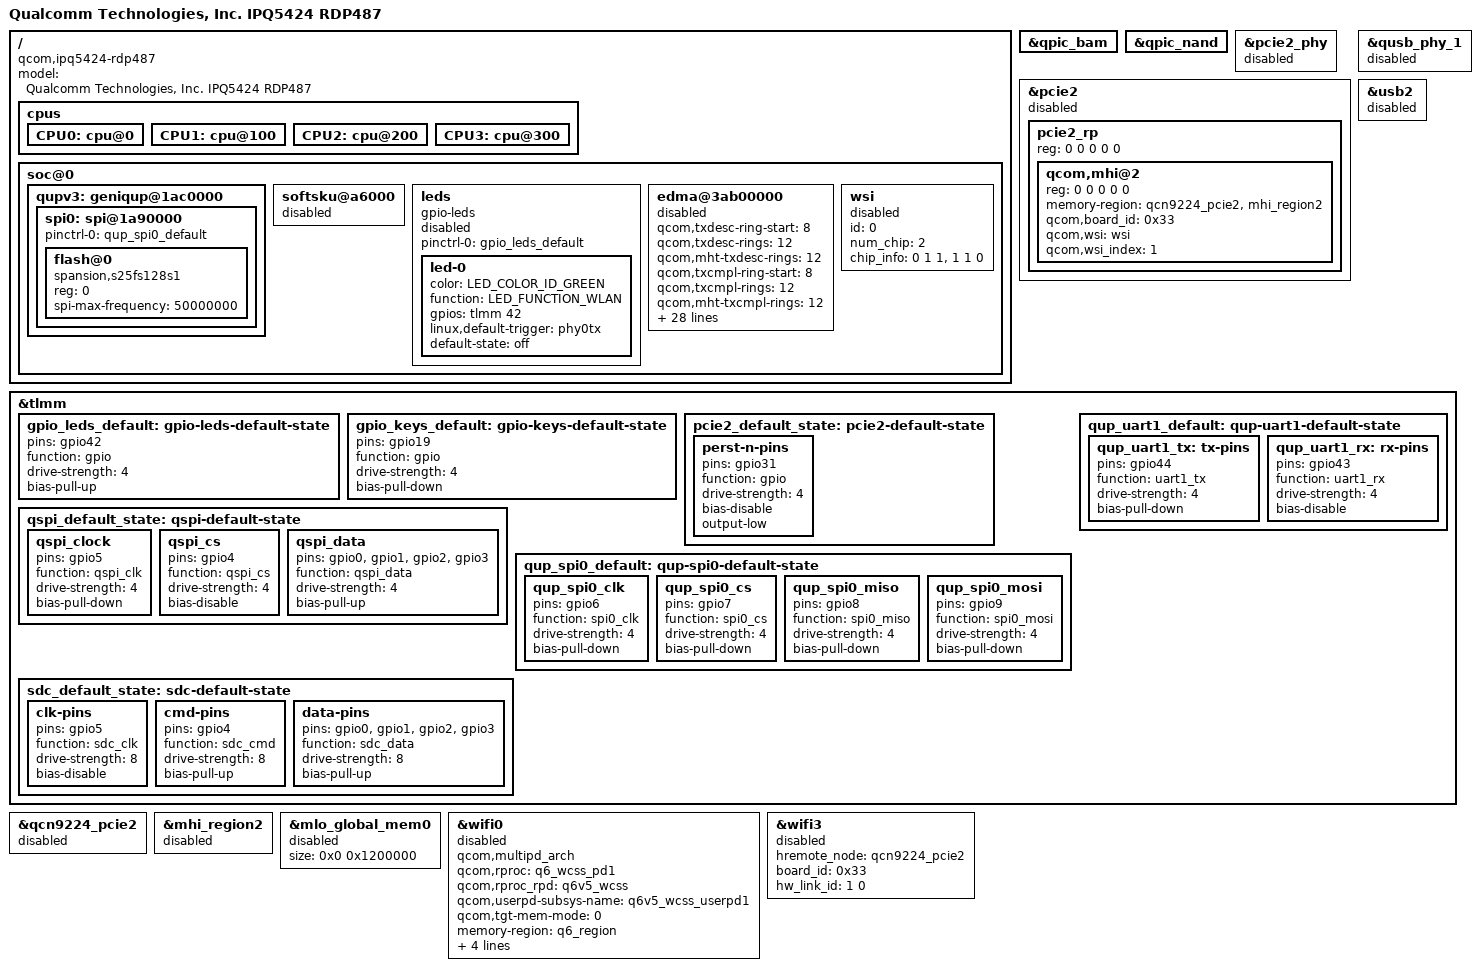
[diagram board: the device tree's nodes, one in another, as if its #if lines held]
// SPDX-License-Identifier: (GPL-2.0+ OR BSD-3-Clause)
/*
 * IPQ5424 RDP487 board device tree source
 *
 * Copyright (c) 2020-2021 The Linux Foundation. All rights reserved.
 * Copyright (c) 2022-2024 Qualcomm Innovation Center, Inc. All rights reserved.
 */

/dts-v1/;

#include "ipq5424-rdp-common.dtsi"
#include "ipq5424-default-memory.dtsi"

/ {
	model = "Qualcomm Technologies, Inc. IPQ5424 RDP487";
	compatible = "qcom,ipq5424-rdp487", "qcom,ipq5424";

	/delete-node/ ipq-debug;
	/delete-node/ pmu;
	/delete-node/ pmu-v7;
	/delete-node/ thermal-zones;

	cpus: cpus {
		CPU0: cpu@0 {
			/delete-property/ clocks;
			/delete-property/ clock-names;
		};

		CPU1: cpu@100 {
			/delete-property/ clocks;
			/delete-property/ clock-names;
		};

		CPU2: cpu@200 {
			/delete-property/ clocks;
			/delete-property/ clock-names;
		};

		CPU3: cpu@300 {
			/delete-property/ clocks;
			/delete-property/ clock-names;
		};
	};

	/delete-node/ opp-table-cpu;

	soc@0 {
		qupv3: geniqup@1ac0000 {

			spi0: spi@1a90000 {
				pinctrl-0 = <&qup_spi0_default>;
				pinctrl-names = "default";
				status = "okay";

				flash@0 {
					compatible = "spansion,s25fs128s1", "jedec,spi-nor";
					#address-cells = <1>;
					#size-cells = <1>;
					reg = <0>;
					spi-max-frequency = <50000000>;
				};
			};
		};

		softsku@a6000 {
			status = "disabled";
		};

		/delete-node/ apss-clock@fa80000;
		/delete-node/ efuse@a4000;
		/delete-node/ thermal-sensor@4a9000;
		/delete-node/ dcc@60ff000;
		/delete-node/ gpio-keys;
		/delete-node/ mmc@7804000;
		/delete-node/ rng@4c3000;

		leds {
			compatible = "gpio-leds";
			pinctrl-0 = <&gpio_leds_default>;
			pinctrl-names = "default";
			status = "disabled";

			led-0 {
				color = <LED_COLOR_ID_GREEN>;
				function = LED_FUNCTION_WLAN;
				gpios = <&tlmm 42 GPIO_ACTIVE_HIGH>;
				linux,default-trigger = "phy0tx";
				default-state = "off";
			};
		};

		/* EDMA host driver configuration for the board */
		edma@3ab00000 {
			qcom,txdesc-ring-start = <8>;		/* Tx desc ring start ID */
			qcom,txdesc-rings = <12>;		/* Total number of Tx desc rings to be provisioned */
			qcom,mht-txdesc-rings = <12>;		/* Extra Tx desc rings to be provisioned for MHT SW ports */
			qcom,txcmpl-ring-start = <8>;		/* Tx complete ring start ID */
			qcom,txcmpl-rings = <12>;		/* Total number of Tx complete rings to be provisioned */
			qcom,mht-txcmpl-rings = <12>;		/* Extra Tx complete rings to be provisioned for mht sw ports. */
			qcom,rxfill-ring-start = <4>;		/* Rx fill ring start ID */
			qcom,rxfill-rings = <4>;		/* Total number of Rx fill rings to be provisioned */
			qcom,rxdesc-ring-start = <20>;		/* Rx desc ring start ID */
			qcom,rxdesc-rings = <4>;		/* Total number of Rx desc rings to be provisioned */
			qcom,rx-page-mode = <0>;		/* Rx fill ring page mode */
			qcom,tx-map-priority-level = <1>;	/* Tx priority level per port */
			qcom,rx-map-priority-level = <1>;	/* Rx priority level per core */
			qcom,ppeds-num = <4>;			/* Number of PPEDS nodes */
			/* PPE-DS node format: <Rx-fill Tx-cmpl Rx Tx Queue-base Queue-count> */
			qcom,ppeds-map = <1 1 1 1 32 8>,	/* PPEDS Node #0 ring and queue map */
					<2 2 2 2 40 8>,		/* PPEDS Node #1 ring and queue map */
					<3 3 3 3 48 8>,		/* PPEDS Node #2 ring and queue map */
					<0 0 0 0 56 8>;		/* PPEDS Node #3 ring and queue map */
			qcom,txdesc-map = <12 13 14 15>,	/* MHT-Port1 per-core Tx ring map */
					<16 17 18 19>,		/* MHT-Port2 per-core Tx ring map */
					<20 21 22 23>,		/* MHT-Port3 per-core Tx ring map */
					<24 25 26 27>,		/* MHT-Port4 per-core Tx ring map */
					<28 29 30 31>;		/* Used only for packets from VP */
			qcom,txdesc-fc-grp-map = <1 2 3 4>;	/* Per GMAC flow control group map */
			qcom,rxfill-map = <4 5 6 7>;		/* Per-core Rx fill ring map */
			qcom,rxdesc-map = <20 21 22 23>;	/* Per-core Rx desc ring map */
			qcom,rx-queue-start = <0>;		/* Rx queue start */
			qcom,rx-ring-queue-map = <0 8 16 24>,	/* Priority 0 queues per-core Rx ring map */
						<1 9 17 25>,	/* Priority 1 queues per-core Rx ring map */
						<2 10 18 26>,	/* Priority 2 queues per-core Rx ring map */
						<3 11 19 27>,	/* Priority 3 queues per-core Rx ring map */
						<4 12 20 28>,	/* Priority 4 queues per-core Rx ring map */
						<5 13 21 29>,	/* Priority 5 queues per-core Rx ring map */
						<6 14 22 30>,	/* Priority 6 queues per-core Rx ring map */
						<7 15 23 31>;	/* Priority 7 queues per-core Rx ring map */
			interrupts = <0 290 4>,			/* Tx complete ring id #8 IRQ info */
					<0 291 4>,		/* Tx complete ring id #9 IRQ info */
					<0 292 4>,		/* Tx complete ring id #10 IRQ info */
					<0 293 4>,		/* Tx complete ring id #11 IRQ info */
					<0 294 4>,		/* Tx complete ring id #12 IRQ info */
					<0 295 4>,		/* Tx complete ring id #13 IRQ info */
					<0 296 4>,		/* Tx complete ring id #14 IRQ info */
					<0 297 4>,		/* Tx complete ring id #15 IRQ info */
					<0 298 4>,		/* Tx complete ring id #16 IRQ info */
					<0 299 4>,		/* Tx complete ring id #17 IRQ info */
					<0 300 4>,		/* Tx complete ring id #18 IRQ info */
					<0 301 4>,		/* Tx complete ring id #19 IRQ info */
					<0 270 4>,		/* Rx desc ring id #20 IRQ info */
					<0 271 4>,		/* Rx desc ring id #21 IRQ info */
					<0 272 4>,		/* Rx desc ring id #22 IRQ info */
					<0 273 4>,		/* Rx desc ring id #23 IRQ info */
					<0 314 4>,		/* Misc error IRQ info */
					<0 283 4>,		/* PPEDS Node #0(TxComp ring id #1) TxComplete IRQ info */
					<0 251 4>,		/* PPEDS Node #0(Rx Desc ring id #1) Rx Desc IRQ info */
					<0 275 4>,		/* PPEDS Node #0(RxFill Desc ring id #1) Rx Fill IRQ info */
					<0 284 4>,		/* PPEDS Node #1(TxComp ring id #2) TxComplete IRQ info */
					<0 252 4>,		/* PPEDS Node #1(Rx Desc ring id #2) Rx Desc IRQ info */
					<0 276 4>,		/* PPEDS Node #1(RxFill Desc ring id #2) Rx Fill IRQ info */
					<0 285 4>,		/* PPEDS Node #2(TxComp ring id #3) TxComplete IRQ info */
                                        <0 253 4>,		/* PPEDS Node #2(Rx Desc ring id #3) Rx Desc IRQ info */
                                        <0 277 4>,		/* PPEDS Node #2(RxFill Desc ring id #3) Rx Fill IRQ info */
					<0 282 4>,		/* PPEDS Node #3(TxComp ring id #0) TxComplete IRQ info */
					<0 250 4>,		/* PPEDS Node #3(Rx Desc ring id #0) Rx Desc IRQ info */
					<0 274 4>,		/* PPEDS Node #3(RxFill Desc ring id #0) Rx Fill IRQ info */
					<0 302 4>,		/* MHT port Tx complete ring id #20 IRQ info */
                                        <0 303 4>,		/* MHT port Tx complete ring id #21 IRQ info */
                                        <0 304 4>,		/* MHT port Tx complete ring id #22 IRQ info */
                                        <0 305 4>,		/* MHT port Tx complete ring id #23 IRQ info */
					<0 306 4>,		/* MHT port Tx complete ring id #24 IRQ info */
					<0 307 4>,		/* MHT port Tx complete ring id #25 IRQ info */
					<0 308 4>,		/* MHT port Tx complete ring id #26 IRQ info */
					<0 309 4>,		/* MHT port Tx complete ring id #27 IRQ info */
					<0 310 4>,		/* MHT port Tx complete ring id #28 IRQ info */
					<0 311 4>,		/* MHT port Tx complete ring id #29 IRQ info */
					<0 312 4>,		/* MHT port Tx complete ring id #30 IRQ info */
					<0 313 4>;		/* MHT port Tx complete ring id #31 IRQ info */
			status = "disabled";
		};

		wsi: wsi {
			id = <0>;
			num_chip = <2>;
			chip_info = <0 1 1>,
				    <1 1 0>;
			status = "disabled";
		};
	};
};

&qpic_bam {
	status = "okay";
};

&qpic_nand {
	status = "okay";
};

&pcie2_phy {
	status = "disabled";
};

&pcie2 {
	status = "disabled";

	pcie2_rp {
		reg = <0 0 0 0 0>;

		qcom,mhi@2 {
			reg = <0 0 0 0 0>;
			memory-region = <&qcn9224_pcie2>, <&mhi_region2>;
			qcom,board_id = <0x33>;
			qcom,wsi = <&wsi>;
			qcom,wsi_index = <1>;
		};
	};
};

&qusb_phy_1 {
	status = "disabled";
};

&usb2 {
	status = "disabled";
};

&tlmm {
	gpio_leds_default: gpio-leds-default-state {
		pins = "gpio42";
		function = "gpio";
		drive-strength = <4>;
		bias-pull-up;
	};

	gpio_keys_default: gpio-keys-default-state {
		pins = "gpio19";
		function = "gpio";
		drive-strength = <4>;
		bias-pull-down;
	};

	pcie2_default_state: pcie2-default-state {
		perst-n-pins {
			pins = "gpio31";
			function = "gpio";
			drive-strength = <4>;
			bias-disable;
			output-low;
		};
	};

	qspi_default_state: qspi-default-state {
		qspi_clock {
			pins = "gpio5";
			function = "qspi_clk";
			drive-strength = <4>;
			bias-pull-down;
		};

		qspi_cs {
			pins = "gpio4";
			function = "qspi_cs";
			drive-strength = <4>;
			bias-disable;
		};

		qspi_data {
			pins = "gpio0", "gpio1", "gpio2", "gpio3";
			function = "qspi_data";
			drive-strength = <4>;
			bias-pull-up;
		};
	};

	qup_spi0_default: qup-spi0-default-state {
		qup_spi0_clk {
			pins = "gpio6";
			function = "spi0_clk";
			drive-strength = <4>;
			bias-pull-down;
		};

		qup_spi0_cs {
			pins = "gpio7";
			function = "spi0_cs";
			drive-strength = <4>;
			bias-pull-down;
		};

		qup_spi0_miso {
			pins = "gpio8";
			function = "spi0_miso";
			drive-strength = <4>;
			bias-pull-down;
		};

		qup_spi0_mosi {
			pins = "gpio9";
			function = "spi0_mosi";
			drive-strength = <4>;
			bias-pull-down;
		};
	};

	qup_uart1_default: qup-uart1-default-state {
		qup_uart1_tx: tx-pins {
			pins = "gpio44";
			function = "uart1_tx";
			drive-strength = <4>;
			bias-pull-down;
		};

		qup_uart1_rx: rx-pins {
			pins = "gpio43";
			function = "uart1_rx";
			drive-strength = <4>;
			bias-disable;
		};
	};

	sdc_default_state: sdc-default-state {
		clk-pins {
			pins = "gpio5";
			function = "sdc_clk";
			drive-strength = <8>;
			bias-disable;
		};

		cmd-pins {
			pins = "gpio4";
			function = "sdc_cmd";
			drive-strength = <8>;
			bias-pull-up;
		};

		data-pins {
			pins = "gpio0", "gpio1", "gpio2", "gpio3";
			function = "sdc_data";
			drive-strength = <8>;
			bias-pull-up;
		};
	};

};

&qcn9224_pcie2 {
	status = "disabled";
};

#if defined(__MHI_BUS_RESERVED_DMA_POOL__)
&mhi_region2 {
	status = "disabled";
};
#endif

&mlo_global_mem0 {
        size = <0x0 0x1200000>;
        status = "disabled";
};

&wifi0 {
	qcom,multipd_arch;
	qcom,rproc = <&q6_wcss_pd1>;
	qcom,rproc_rpd = <&q6v5_wcss>;
	qcom,userpd-subsys-name = "q6v5_wcss_userpd1";
	qcom,tgt-mem-mode = <0>;
	memory-region = <&q6_region>;
	qcom,wsi = <&wsi>;
	qcom,wsi_index = <0>;
	qcom,board_id = <0x12>;
	hw_link_id = <0 0>;
	status = "disabled";
};

&wifi3 {
	hremote_node = <&qcn9224_pcie2>;
	board_id = <0x33>;
	hw_link_id = <1 0>;
	status = "disabled";
};
